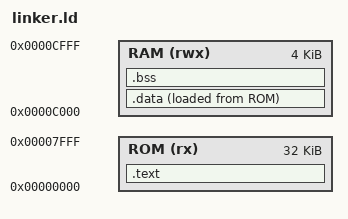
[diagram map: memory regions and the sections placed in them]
ENTRY(_start)

MEMORY
{
  ROM (rx)  : ORIGIN = 0x00000000, LENGTH = 0x8000
  RAM (rwx) : ORIGIN = 0x0000c000, LENGTH = 0x1000
}

SECTIONS
{
  .text : {
    KEEP(*(.text.start))
    *(.text*)
    *(.rodata*)
  } > ROM

  .data : {
    *(.data*)
  } > RAM AT > ROM

  .bss : {
    *(.bss*)
    *(COMMON)
  } > RAM

  _stack_top = ORIGIN(RAM) + LENGTH(RAM);
}
